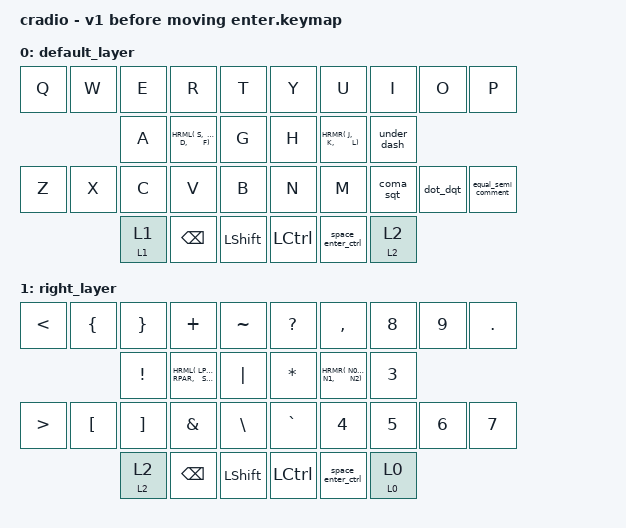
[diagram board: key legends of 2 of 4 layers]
// Copyright (c) 2022 The ZMK Contributors
// SPDX-License-Identifier: MIT

#include <behaviors.dtsi>
#include <dt-bindings/zmk/keys.h>
#include <dt-bindings/zmk/bt.h>
#include <dt-bindings/zmk/mouse.h>
#include <dt-bindings/zmk/outputs.h>

#include "cradio.dtsi"

// Home row mods macro
#define HRML(k1,k2,k3) &ht LGUI k1  &ht LALT k2  &ht LCTRL k3
#define HRMR(k1,k2,k3) &ht LCTRL k1 &ht LALT k2  &ht LGUI k3 
#define HRMR2(k1,k2)  &ht LALT k1  &ht LGUI k2 

#define MO_TOG(layer) &mo_tog layer layer   // Macro to apply momentary-layer-on-hold/toggle-layer-on-tap to a specific layer




/ {
    
    
    combos {
        compatible = "zmk,combos";
        combo_undo {
            timeout-ms = <50>;
            key-positions = <20 21>;
            bindings = <&kp LC(Z)>;
            require-prior-idle-ms = <50>;
        };
        combo_copy {
            timeout-ms = <50>;
            key-positions = <21 22>;
            bindings = <&kp LC(C)>;
            require-prior-idle-ms = <50>;
        };
        combo_paste {
            timeout-ms = <50>;
            key-positions = <22 23>;
            bindings = <&kp LC(V)>;
            require-prior-idle-ms = <50>;
        };
        combo_delete {
            timeout-ms = <50>;
            key-positions = <5 6>;
            bindings = <&kp DEL>;
            require-prior-idle-ms = <50>;
        };
    };

    behaviors {
        // for home row mods
        ht: hold_tap {
            compatible = "zmk,behavior-hold-tap";
            #binding-cells = <2>;
            flavor = "tap-preferred";
            tapping-term-ms = <220>;
            quick-tap-ms = <150>;
            require-prior-idle-ms = <100>;
            bindings = <&kp>, <&kp>;
        };
        // momentary or toggle switch
        mo_tog: behavior_mo_tog {
            compatible = "zmk,behavior-hold-tap";
            #binding-cells = <2>;
            flavor = "hold-preferred";
            tapping-term-ms = <200>;
            bindings = <&mo>, <&to>;
        };

        bspc_del: backspace_delete {
            compatible = "zmk,behavior-mod-morph";
            #binding-cells = <0>;
            bindings = <&kp BSPC>, <&kp DEL>;
            mods = <(MOD_LCTL)>;
        };
    
        space_shift_enter: space_shift_enter {
            compatible = "zmk,behavior-mod-morph";
            #binding-cells = <0>;
            bindings = <&kp LC(ENTER)>, <&kp LS(ENTER)>;
            mods = <(MOD_LALT)>;
        };
        space_enter: space_enter {
            compatible = "zmk,behavior-mod-morph";
            #binding-cells = <0>;
            bindings = <&kp ENTER>, <&space_shift_enter>;
            mods = <(MOD_LCTL)>;
        };
        space_enter_ctrl: space_enter_ctrl {
            compatible = "zmk,behavior-mod-morph";
            #binding-cells = <0>;
            bindings = <&kp SPACE>, <&space_enter>;
            mods = <(MOD_LSFT)>;
        };


        coma_sqt: comma_undescore {
            compatible = "zmk,behavior-mod-morph";
            #binding-cells = <0>;
            bindings = <&kp COMMA>, <&kp SQT>;
            mods = <(MOD_LSFT)>;
        };
        dot_dqt: dot_dqt {
            compatible = "zmk,behavior-mod-morph";
            #binding-cells = <0>;
            bindings = <&kp DOT>, <&kp DQT>;
            mods = <(MOD_LSFT)>;
        };
        under_dash: under_dash {
            compatible = "zmk,behavior-mod-morph";
            #binding-cells = <0>;
            bindings = <&kp UNDER>, <&kp MINUS>;
            mods = <(MOD_LSFT)>;
        };

        semi_comment: semi_comment {
            compatible = "zmk,behavior-mod-morph";
            #binding-cells = <0>;
            bindings = <&kp SEMI>, <&kp SLASH>;
            mods = <(MOD_LCTL)>;
            keep-mods = <(MOD_LCTL)>;
        };
        equal_semi_comment: equal_semi_comment {
            compatible = "zmk,behavior-mod-morph";
            #binding-cells = <0>;
            bindings = <&kp EQUAL>, <&semi_comment>;
            mods = <(MOD_LSFT)>;
        };
        
    };



    keymap {
        compatible = "zmk,keymap";
        default_layer {
            bindings = <
        //╭──────────┬──────────┬──────────┬──────────┬──────────╮   ╭──────────┬──────────┬──────────┬──────────┬──────────╮
        //│  Q       │  W       │  E       │  R       │  T       │   │  Y       │  U       │  I       │  O       │  P       │
            &kp Q      &kp W      &kp E      &kp R      &kp T          &kp Y      &kp U      &kp I      &kp O      &kp P
        //├──────────┼──────────┼──────────┼──────────┼──────────┤   ├──────────┼──────────┼──────────┼──────────┼──────────┤
        //│  A       │  S  Win  │  D   Alt │  F       │  G       │   │  H       │  J       │  K   alt │  L   win │   _  -   │
            &kp A  HRML( S,         D,        F)      &kp G          &kp H     HRMR( J,       K,         L)      &under_dash
        //├──────────┼──────────┼──────────┼──────────┼──────────┤   ├──────────┼──────────┼──────────┼──────────┼──────────┤
        //│  Z       │  X       │  C       │  V       │  B       │   │  N       │  M       │ , '      │ . "      │ = ; RC(/)│
            &kp Z      &kp X      &kp C      &kp V      &kp B          &kp N      &kp M    &coma_sqt  &dot_dqt  &equal_semi_comment
        //╰──────────┴──────────┴──────────┼──────────┼──────────┤   ├──────────┼──────────┼──────────┴──────────┴──────────╯
                             &mo_tog 1 1   &kp BSPC    &kp LSHIFT    &kp LCTRL  &space_enter_ctrl   &mo_tog 2 2  
        //                                 ╰──────────┴──────────╯   ╰──────────┴──────────╯
            >;
        };

        right_layer {
            bindings = <
        //╭──────────┬──────────┬──────────┬──────────┬──────────╮   ╭──────────┬──────────┬──────────┬──────────┬──────────╮
        //│  <       │  {       │	  }    │     +    │     ~    │   │   ?      │   ,      │    8     │   9      │    .     │
            &kp LT   &kp LBRC       &kp RBRC  &kp PLUS  &kp TILDE      &kp QMARK   &kp COMMA  &kp N8  &kp N9    &kp DOT
        //├──────────┼──────────┼──────────┼──────────┼──────────┤   ├──────────┼──────────┼──────────┼──────────┼──────────┤
        //│   !      │ 	 (      │  )       │  /       │   |      │   │   *      │   0      │  1       │   2      │  3       │
            &kp EXCL  HRML( LPAR,   RPAR,    SLASH)   &kp PIPE          &kp STAR   HRMR( N0,    N1,        N2)   &kp N3
        //├──────────┼──────────┼──────────┼──────────┼──────────┤   ├──────────┼──────────┼──────────┼──────────┼──────────┤
        //│    >     │  [       │  ]       │  &       │  \       │   │    `     │     4    │   5      │   6      │   7      │
           &kp GT    &kp LBKT  &kp RBKT     &kp AMPS    &kp BSLH         &kp GRAVE     &kp N4     &kp N5     &kp N6     &kp N7
        //╰──────────┴──────────┴──────────┼──────────┼──────────┤   ├──────────┼──────────┼──────────┴──────────┴──────────╯
                              &mo_tog 2 2   &kp BSPC   &kp LSHIFT    &kp LCTRL   &space_enter_ctrl    &mo_tog 0 0 
        //                                 ╰──────────┴──────────╯   ╰──────────┴──────────╯
            >;
        };

        left_layer {
            bindings = <
        //╭──────────┬──────────┬──────────┬──────────┬──────────╮   ╭──────────┬──────────┬──────────┬──────────┬──────────╮
        //│    F11   │  Home    │    UP    │  END     │ Vol up   │   │ ^ & UpLyr│ MousBtn4 │  ESC     │ MousBtn5 │ BrightUp │
            &kp F11     &kp HOME   &kp UP   &kp END   &kp C_VOL_UP     &lt 3 CARET  &mkp MB4  &kp ESC   &mkp MB5   &kp C_BRI_UP
        //├──────────┼──────────┼──────────┼──────────┼──────────┤   ├──────────┼──────────┼──────────┼──────────┼──────────┤
        //│  TAB     │  Left    │  Down    │  RIGHT   │ mute     │   | MousMid  │LeftClick │   #      │  :       │rightClick│
            &kp TAB   &kp LEFT   &kp DOWN   &kp RIGHT  &kp C_MUTE    &mkp MCLK  &mkp LCLK  HRMR2( HASH, COLON)   &mkp RCLK
        //├──────────┼──────────┼──────────┼──────────┼──────────┤   ├──────────┼──────────┼──────────┼──────────┼──────────┤
        //│   F4     │   PgUp   │Play/Pause│  PgDwn   │ Vol down │   │ PRintScrn|  @       │  %       │  $       │ BrightDwn│
            &kp F4   &kp PG_UP   &kp C_PP  &kp PG_DN  &kp C_VOL_DN    &kp PSCRN   &kp AT  &kp PRCNT   &kp DLLR   &kp C_BRI_DN
        //╰──────────┴──────────┴──────────┼──────────┼──────────┤   ├──────────┼──────────┼──────────┴──────────┴──────────╯
                            &mo_tog 1 1   &kp BSPC     &kp LSHIFT      &kp LCTRL     &space_enter_ctrl    &mo_tog 0 0 
        //                                 ╰──────────┴──────────╯   ╰──────────┴──────────╯
            >;
        };

        tri_layer {
            bindings = <
        //╭──────────┬──────────┬──────────┬──────────┬──────────╮   ╭──────────┬──────────┬──────────┬──────────┬──────────╮
        //│  BT0     │  Bt1     │     BT2  │  BT3     | CLEAR BT │   │KeepUpLaye│          │          │          │          │
      &bt BT_SEL 0 &bt BT_SEL 1 &bt BT_SEL 2 &bt BT_SEL 3  &bt BT_CLR     &trans     &none     &none    &none      &none
        //├──────────┼──────────┼──────────┼──────────┼──────────┤   ├──────────┼──────────┼──────────┼──────────┼──────────┤
        //│USB BLE TG│ CapsLock │ PrevSong │ NextSong │          │   │          │          │          │          │          │
         &out OUT_TOG  &kp CAPS   &kp C_PREV    &kp C_NEXT   &none          &none     &none         &none   &none       &none    
        //├──────────┼──────────┼──────────┼──────────┼──────────┤   ├──────────┼──────────┼──────────┼──────────┼──────────┤
        //│ BtDiscon0| BtDiscon1│ BtDiscon2│ RESET    │BOOTLOADER│   │BOOTLOADER│ RESET    │          │          │          │
        &bt BT_DISC 0 &bt BT_DISC 1 &bt BT_DISC 2 &sys_reset &bootloader    &bootloader  &sys_reset   &none     &none     &none
        //╰──────────┴──────────┴──────────┼──────────┼──────────┤   ├──────────┼──────────┼──────────┴──────────┴──────────╯
                                    &none        &none     &none         &none     &none    &none   
        //                                 ╰──────────┴──────────╯   ╰──────────┴──────────╯
            >;
        };
    };
};
